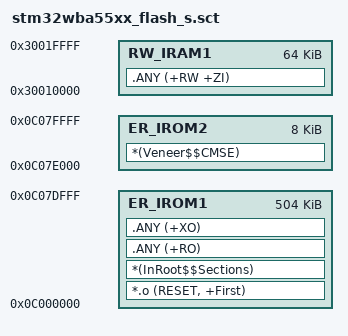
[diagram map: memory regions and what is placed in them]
; *************************************************************
; *** Scatter-Loading Description File generated by uVision ***
; *************************************************************

LR_IROM1 0x0c000000 0x0007e000  {    ; load region size_region
  ER_IROM1 0x0c000000 0x0007e000  {  ; load address = execution address
   *.o (RESET, +First)
   *(InRoot$$Sections)
   .ANY (+RO)
   .ANY (+XO)
  }
;***region***;
;***endregion***;
  RW_IRAM1 0x30010000 0x00010000  {  ; RW data
   .ANY (+RW +ZI)
  }
}

LR_IROM2 0x0c07e000 0x00002000  {    ; load region size_region
  ER_IROM2 0x0c07e000 0x00002000  {  ; load address = execution address
   *(Veneer$$CMSE)                   ; check with partition.h
  }
}
/*-Start of  regions- Auto-generated By STM32CubeMX-*/
